# MKW22D5 register map
Vendor: Freescale Semiconductor, Inc.; Series: Kinetis_W; File version: 1.6
CPU: CM4 r0p1, little endian, no MPU, no FPU, VTOR, 4 interrupt priority bits
Registers are 32-bit, read-write, reset 0x0 unless marked. A register's access mark holds for its fields unless they carry their own. Offsets are from the block's base; [hi:lo] are bit positions; {n}, {i} and the like mark numbered series.

## FTFL_FlashConfig — Flash configuration field
Base 0x00000400; register names take the prefix NV_
0x00 BACKKEY3 8-bit ro reset 0xFF — Backdoor Comparison Key 3.
  [7:0] KEY — Backdoor Comparison Key.
0x01 BACKKEY2 8-bit ro reset 0xFF — Backdoor Comparison Key 2.
  [7:0] KEY — Backdoor Comparison Key.
0x02 BACKKEY1 8-bit ro reset 0xFF — Backdoor Comparison Key 1.
  [7:0] KEY — Backdoor Comparison Key.
0x03 BACKKEY0 8-bit ro reset 0xFF — Backdoor Comparison Key 0.
  [7:0] KEY — Backdoor Comparison Key.
0x04 BACKKEY7 8-bit ro reset 0xFF — Backdoor Comparison Key 7.
  [7:0] KEY — Backdoor Comparison Key.
0x05 BACKKEY6 8-bit ro reset 0xFF — Backdoor Comparison Key 6.
  [7:0] KEY — Backdoor Comparison Key.
0x06 BACKKEY5 8-bit ro reset 0xFF — Backdoor Comparison Key 5.
  [7:0] KEY — Backdoor Comparison Key.
0x07 BACKKEY4 8-bit ro reset 0xFF — Backdoor Comparison Key 4.
  [7:0] KEY — Backdoor Comparison Key.
0x08 FPROT3 8-bit ro reset 0xFF — Non-volatile P-Flash Protection 1 - Low Register
  [7:0] PROT — P-Flash Region Protect
0x09 FPROT2 8-bit ro reset 0xFF — Non-volatile P-Flash Protection 1 - High Register
  [7:0] PROT — P-Flash Region Protect
0x0A FPROT1 8-bit ro reset 0xFF — Non-volatile P-Flash Protection 0 - Low Register
  [7:0] PROT — P-Flash Region Protect
0x0B FPROT0 8-bit ro reset 0xFF — Non-volatile P-Flash Protection 0 - High Register
  [7:0] PROT — P-Flash Region Protect
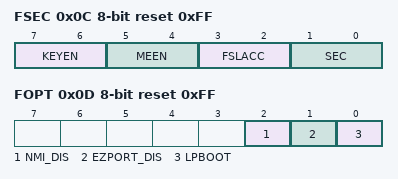
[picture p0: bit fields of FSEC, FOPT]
0x0C FSEC 8-bit ro reset 0xFF — Non-volatile Flash Security Register
  [7:6] KEYEN — Backdoor Key Security Enable
    2=Backdoor key access enabled; 3=Backdoor key access disabled
  [5:4] MEEN
    2=Mass erase is disabled; 3=Mass erase is enabled
  [3:2] FSLACC — Freescale Failure Analysis Access Code
    2=Freescale factory access denied; 3=Freescale factory access granted
  [1:0] SEC — Flash Security
    2=MCU security status is unsecure; 3=MCU security status is secure
0x0D FOPT 8-bit ro reset 0xFF — Non-volatile Flash Option Register
  [2] NMI_DIS
    0=NMI interrupts are always blocked; 1=NMI_b pin/interrupts reset default to enabled
  [1] EZPORT_DIS
    0=EzPort operation is disabled; 1=EzPort operation is enabled
  [0] LPBOOT
    0=Low-power boot; 1=Normal boot
0x0E FEPROT 8-bit ro reset 0xFF — Non-volatile EERAM Protection Register
  [7:0] EPROT
0x0F FDPROT 8-bit ro reset 0xFF — Non-volatile D-Flash Protection Register
  [7:0] DPROT — D-Flash Region Protect

## DMAMUX — DMA channel multiplexor
Base 0x40021000; register names take the prefix DMAMUX_
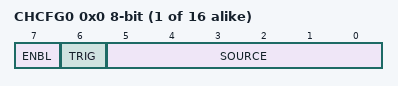
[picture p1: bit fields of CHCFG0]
{0x0+i} CHCFG{i} (i=0..15) 8-bit — Channel Configuration register
  [7] ENBL — DMA Channel Enable
    0=DMA channel is disabled. This mode is primarily used during configuration of the DMA Mux. The DMA has separate channel enables/disables, which should be used to disable or re-configure a DMA channel.; 1=DMA channel is enabled
  [6] TRIG — DMA Channel Trigger Enable
    0=Triggering is disabled. If triggering is disabled, and the ENBL bit is set, the DMA Channel will simply route the specified source to the DMA channel. (Normal mode); 1=Triggering is enabled. If triggering is enabled, and the ENBL bit is set, the DMAMUX is in Periodic Trigger mode.
  [5:0] SOURCE — DMA Channel Source (Slot)
    0=Disable_Signal; 2=UART0_Rx_Signal; 3=UART0_Tx_Signal; 4=UART1_Rx_Signal; 5=UART1_Tx_Signal; 6=UART2_Rx_Signal; 7=UART2_Tx_Signal; 8=UART3_Rx_Signal; 9=UART3_Tx_Signal; 14=I2S0_Rx_Signal; 15=I2S0_Tx_Signal; 16=SPI0_Rx_Signal; 17=SPI0_Tx_Signal; 18=SPI1_Rx_Signal; 19=SPI1_Tx_Signal; 22=I2C0_Signal; 23=I2C1_Signal; {v}=FTM0_Channel{v-24}_Signal (v=24..31); 32=FTM1_Channel0_Signal; 33=FTM1_Channel1_Signal; 34=FTM2_Channel0_Signal; 35=FTM2_Channel1_Signal; 40=ADC0_Signal; 42=CMP0_Signal; 43=CMP1_Signal; 47=CMT_Signal; 48=PDB_Signal; 49=PortA_Signal; 50=PortB_Signal; 51=PortC_Signal; 52=PortD_Signal; 53=PortE_Signal; {v}=AlwaysOn{v}_Signal (v=54..63)

## Notices in the file
Redistribution and use in source and binary forms, with or without modification,
are permitted provided that the following conditions are met:
o Redistributions of source code must retain the above copyright notice, this list
of conditions and the following disclaimer.
o Redistributions in binary form must reproduce the above copyright notice, this
list of conditions and the following disclaimer in the documentation and/or
other materials provided with the distribution.
o Neither the name of Freescale Semiconductor, Inc. nor the names of its
contributors may be used to endorse or promote products derived from this
software without specific prior written permission.
THIS SOFTWARE IS PROVIDED BY THE COPYRIGHT HOLDERS AND CONTRIBUTORS "AS IS" AND
ANY EXPRESS OR IMPLIED WARRANTIES, INCLUDING, BUT NOT LIMITED TO, THE IMPLIED
WARRANTIES OF MERCHANTABILITY AND FITNESS FOR A PARTICULAR PURPOSE ARE
DISCLAIMED. IN NO EVENT SHALL THE COPYRIGHT HOLDER OR CONTRIBUTORS BE LIABLE FOR
ANY DIRECT, INDIRECT, INCIDENTAL, SPECIAL, EXEMPLARY, OR CONSEQUENTIAL DAMAGES
(INCLUDING, BUT NOT LIMITED TO, PROCUREMENT OF SUBSTITUTE GOODS OR SERVICES;
LOSS OF USE, DATA, OR PROFITS; OR BUSINESS INTERRUPTION) HOWEVER CAUSED AND ON
ANY THEORY OF LIABILITY, WHETHER IN CONTRACT, STRICT LIABILITY, OR TORT
(INCLUDING NEGLIGENCE OR OTHERWISE) ARISING IN ANY WAY OUT OF THE USE OF THIS
SOFTWARE, EVEN IF ADVISED OF THE POSSIBILITY OF SUCH DAMAGE.
